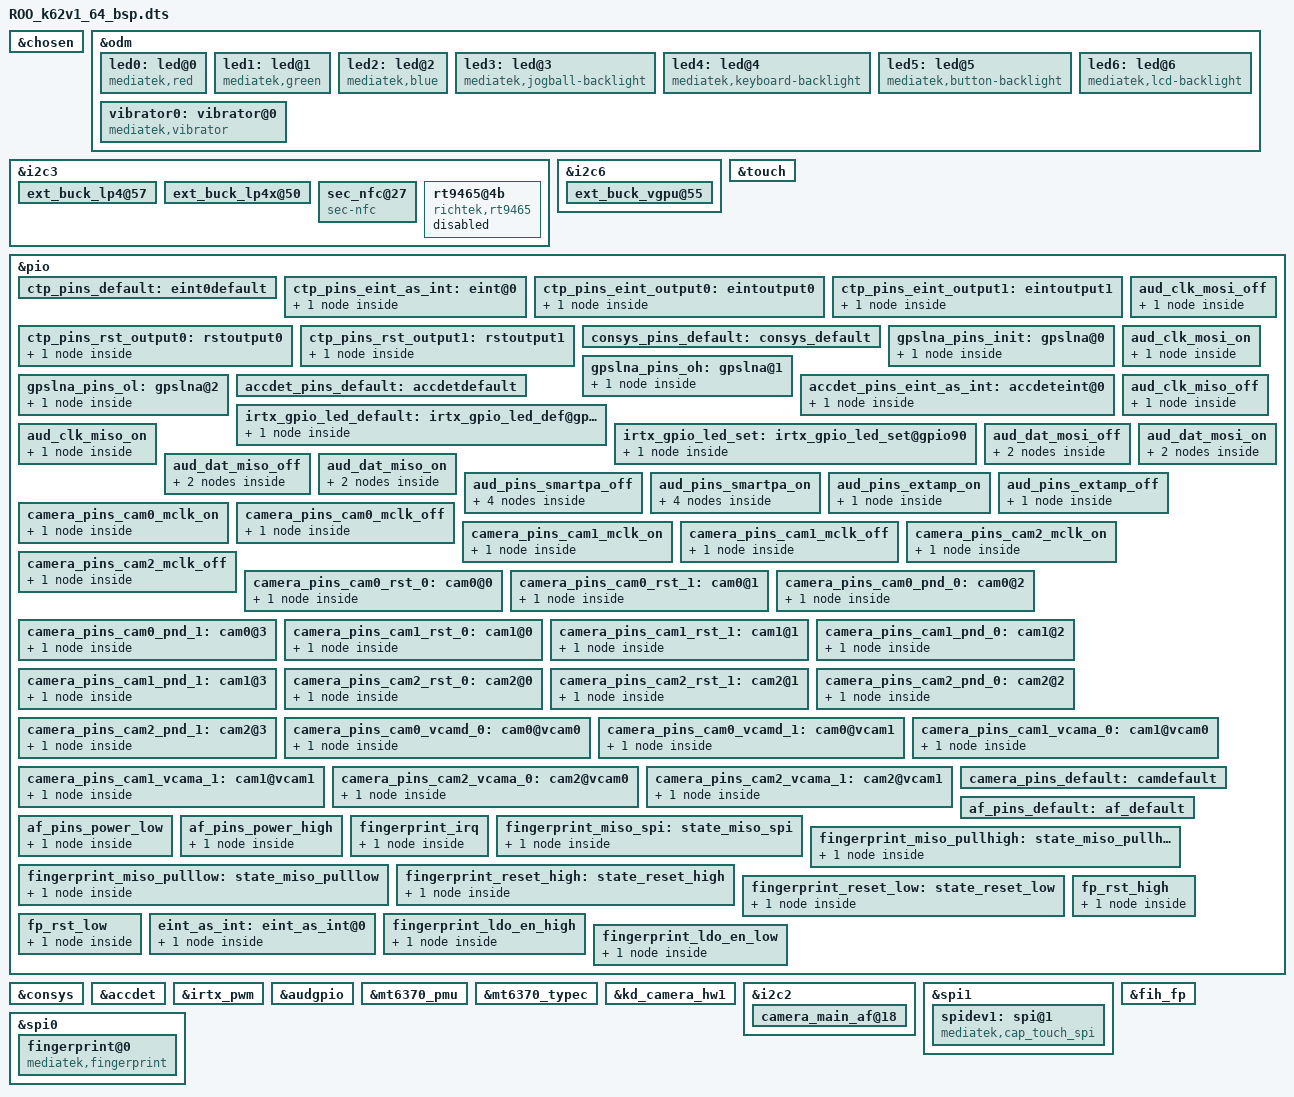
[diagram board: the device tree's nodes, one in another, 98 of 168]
#include <dt-bindings/interrupt-controller/arm-gic.h>
#include <dt-bindings/interrupt-controller/irq.h>
#include <dt-bindings/pinctrl/mt6765-pinfunc.h>
#include <dt-bindings/clock/mt6765-clk.h>

/dts-v1/;
/plugin/;

/* chosen */
&chosen {

	/* fpga may has no lk, we need to specify display info here */
	/* fb buffer is reserved using this dts by memory node above */
	atag,videolfb-fb_base_h = <0x0>;
	atag,videolfb-fb_base_l = <0x5e605000>;
	atag,videolfb-islcmfound = <1>;
	/* because no lk, so lcm is not inited */
	atag,videolfb-islcm_inited = <0>;
	atag,videolfb-fps= <6000>;
	atag,videolfb-vramSize= <0x017bb000>;
	atag,videolfb-lcmname= "ili9881h_hd720plus_dsi_vdo_dj";
};

&odm {
	led0:led@0 {
		compatible = "mediatek,red";
		led_mode = <0>;
		data = <1>;
		pwm_config = <0 0 0 0 0>;
	};
	led1:led@1 {
		compatible = "mediatek,green";
		led_mode = <0>;
		data = <1>;
		pwm_config = <0 0 0 0 0>;
	};
	led2:led@2 {
		compatible = "mediatek,blue";
		led_mode = <0>;
		data = <1>;
		pwm_config = <0 0 0 0 0>;
	};
	led3:led@3 {
		compatible = "mediatek,jogball-backlight";
		led_mode = <0>;
		data = <1>;
		pwm_config = <0 0 0 0 0>;
	};
	led4:led@4 {
		compatible = "mediatek,keyboard-backlight";
		led_mode = <0>;
		data = <1>;
		pwm_config = <0 0 0 0 0>;
	};
	led5:led@5 {
		compatible = "mediatek,button-backlight";
		led_mode = <0>;
		data = <1>;
		pwm_config = <0 0 0 0 0>;
	};
	led6:led@6 {
		compatible = "mediatek,lcd-backlight";
		led_mode = <5>;
		data = <1>;
		pwm_config = <0 3 0 0 0>;
	};
	vibrator0:vibrator@0 {
		compatible = "mediatek,vibrator";
		vib_timer = <50>;
		vib_limit = <0>;
		vib_vol= <9>;
	};
};

&i2c3 {
	ext_buck_lp4@57 {
		regulator-name ="ext_buck_vdd2";
		regulator-min-microvolt = <300000>;
		regulator-max-microvolt = <1300000>;
		vsel_pin = <0>;
	};

	ext_buck_lp4x@50 {
		regulator-name ="ext_buck_vddq";
		regulator-min-microvolt = <300000>;
		regulator-max-microvolt = <1300000>;
		vsel_pin = <1>;
	};
};

&i2c6 {
	ext_buck_vgpu@55 {
		regulator-name ="ext_buck_vgpu";
		regulator-min-microvolt = <300000>;
		regulator-max-microvolt = <1300000>;
		vsel_pin = <2>;
	};
};
/* TOUCH start */
&touch {
	tpd-resolution = <720 1440>;
	use-tpd-button = <0>;
	tpd-key-num = <3>;
	tpd-key-local= <139 172 158 0>;
	tpd-key-dim-local = <90 883 100 40 230 883 100 40 370 883 100 40 0 0 0 0>;
	tpd-max-touch-num = <5>;
	tpd-filter-enable = <1>;
	tpd-filter-pixel-density = <146>;
	tpd-filter-custom-prameters = <0 0 0 0 0 0 0 0 0 0 0 0>;
	tpd-filter-custom-speed = <0 0 0>;
	pinctrl-names = "default", "state_eint_as_int", "state_eint_output0", "state_eint_output1",
		"state_rst_output0", "state_rst_output1";
	pinctrl-0 = <&ctp_pins_default>;
	pinctrl-1 = <&ctp_pins_eint_as_int>;
	pinctrl-2 = <&ctp_pins_eint_output0>;
	pinctrl-3 = <&ctp_pins_eint_output1>;
	pinctrl-4 = <&ctp_pins_rst_output0>;
	pinctrl-5 = <&ctp_pins_rst_output1>;
	status = "okay";
};
&pio {
	ctp_pins_default: eint0default {
	};
	ctp_pins_eint_as_int: eint@0 {
		pins_cmd_dat {
			pinmux = <PINMUX_GPIO0__FUNC_GPIO0>;
			slew-rate = <0>;
			bias-disable;
		};
	};
	ctp_pins_eint_output0: eintoutput0 {
		pins_cmd_dat {
			pinmux = <PINMUX_GPIO0__FUNC_GPIO0>;
			slew-rate = <1>;
			output-low;
		};
	};
	ctp_pins_eint_output1: eintoutput1 {
		pins_cmd_dat {
			pinmux = <PINMUX_GPIO0__FUNC_GPIO0>;
			slew-rate = <1>;
			output-high;
		};
	};
	ctp_pins_rst_output0: rstoutput0 {
		pins_cmd_dat {
			pinmux = <PINMUX_GPIO174__FUNC_GPIO174>;
			slew-rate = <1>;
			output-low;
		};
	};
	ctp_pins_rst_output1: rstoutput1 {
		pins_cmd_dat {
			pinmux = <PINMUX_GPIO174__FUNC_GPIO174>;
			slew-rate = <1>;
			output-high;
		};
	};
};
/* TOUCH end */

/* CONSYS GPIO standardization */
&pio {
	consys_pins_default: consys_default {
	};
	gpslna_pins_init: gpslna@0 {
		pins_cmd_dat {
			pinmux = <PINMUX_GPIO91__FUNC_GPIO91>;
			slew-rate = <0>;
			bias-disable;
			output-low;
		};
	};
	gpslna_pins_oh: gpslna@1 {
		pins_cmd_dat {
			pinmux = <PINMUX_GPIO91__FUNC_GPIO91>;
			slew-rate = <1>;
			output-high;
		};
	};
	gpslna_pins_ol: gpslna@2 {
		pins_cmd_dat {
			pinmux = <PINMUX_GPIO91__FUNC_GPIO91>;
			slew-rate = <1>;
			output-low;
		};
	};
};
&consys {
	pinctrl-names = "default", "gps_lna_state_init",
		"gps_lna_state_oh", "gps_lna_state_ol";
	pinctrl-0 = <&consys_pins_default>;
	pinctrl-1 = <&gpslna_pins_init>;
	pinctrl-2 = <&gpslna_pins_oh>;
	pinctrl-3 = <&gpslna_pins_ol>;
	status = "okay";
};
/* CONSYS end */
/* J6000363 - edith.y.hu
   NFC I2C config @{ */
/* J6000504 - roy.zy.shang
   NFC I2C config @{ */
/* NFC start */
&i2c3 {
        sec_nfc@27 {
        compatible = "sec-nfc";
        reg = <0x27>;
        pvdd-gpio = <&pio 178 0x0>;
        ven-gpio = <&pio 173 0x0>;
        irq-gpio = <&pio 10 0x0>;
        firm-gpio = <&pio 172 0x0>;
        clk_req-gpio = <&pio 89 0x0>;
    };
};

/* NFC end */
/* NFC I2C config @} */

/* accdet start */
&accdet {
	accdet-mic-vol = <6>;
	headset-mode-setting = <0x500 0x500 1 0x1f0 0x800 0x800 0x20 0x44>;
	accdet-plugout-debounce = <1>;
	accdet-mic-mode = <1>;
	headset-eint-level-pol = <8>;
	headset-three-key-threshold = <0 80 220 400>;
	headset-three-key-threshold-CDD = <0 121 192 600>;
	headset-four-key-threshold = <0 58 121 192 400>;
	pinctrl-names = "default", "state_eint_as_int";
	pinctrl-0 = <&accdet_pins_default>;
	pinctrl-1 = <&accdet_pins_eint_as_int>;
	status = "okay";
};
&pio {
	accdet_pins_default: accdetdefault {
	};
	accdet_pins_eint_as_int: accdeteint@0 {
		pins_cmd_dat {
			pinmux = <PINMUX_GPIO9__FUNC_GPIO9>;
			slew-rate = <0>;
			bias-disable;
		};
	};
};
/* accdet end */

/* battery end */
/*&bat_gm30 {
	EMBEDDED_SEL = <(0)>;
};*/
/* battery end */

/* IRTX GPIO end */
&irtx_pwm {
	pinctrl-names = "irtx_gpio_led_default", "irtx_gpio_led_set";
	pinctrl-0 = <&irtx_gpio_led_default>;
	pinctrl-1 = <&irtx_gpio_led_set>;
	status = "okay";
};
&pio {
	irtx_gpio_led_default:irtx_gpio_led_def@gpio90 {
		pins_cmd_dat {
			pinmux = <PINMUX_GPIO90__FUNC_GPIO90>;
			slew-rate = <1>;
			bias-disable;
			output-low;
			input-schmitt-enable = <0>;
		};
	};

	irtx_gpio_led_set:irtx_gpio_led_set@gpio90 {
		pins_cmd_dat {
			pinmux = <PINMUX_GPIO90__FUNC_PWM0>;
			slew-rate = <1>;
			output-high;
		};
	};
};
/* IRTX GPIO Settings -End */

/* AUDIO GPIO standardization */
&audgpio {
	pinctrl-names = "aud_clk_mosi_off",
			"aud_clk_mosi_on",
			"aud_clk_miso_off",
			"aud_clk_miso_on",
			"aud_dat_mosi_off",
			"aud_dat_mosi_on",
			"aud_dat_miso_off",
			"aud_dat_miso_on",
			"aud_smartpa_off",
			"aud_smartpa_on",
			"extamp-pullhigh",
			"extamp-pulllow";
	pinctrl-0 = <&aud_clk_mosi_off>;
	pinctrl-1 = <&aud_clk_mosi_on>;
	pinctrl-2 = <&aud_clk_miso_off>;
	pinctrl-3 = <&aud_clk_miso_on>;
	pinctrl-4 = <&aud_dat_mosi_off>;
	pinctrl-5 = <&aud_dat_mosi_on>;
	pinctrl-6 = <&aud_dat_miso_off>;
	pinctrl-7 = <&aud_dat_miso_on>;
	pinctrl-8 = <&aud_pins_smartpa_off>;
	pinctrl-9 = <&aud_pins_smartpa_on>;
	pinctrl-10 = <&aud_pins_extamp_on>;
	pinctrl-11 = <&aud_pins_extamp_off>;
	status = "okay";
};

&pio {
	aud_clk_mosi_off: aud_clk_mosi_off {
		pins_cmd0_dat {
			pinmux = <PINMUX_GPIO136__FUNC_GPIO136>;
		};
	};

	aud_clk_mosi_on: aud_clk_mosi_on {
		pins_cmd0_dat {
			pinmux = <PINMUX_GPIO136__FUNC_AUD_CLK_MOSI>;
		};
	};

	aud_clk_miso_off: aud_clk_miso_off {
		pins_cmd0_dat {
			pinmux = <PINMUX_GPIO140__FUNC_GPIO140>;
		};
	};

	aud_clk_miso_on: aud_clk_miso_on {
		pins_cmd0_dat {
			pinmux = <PINMUX_GPIO140__FUNC_AUD_CLK_MISO>;
		};
	};

	aud_dat_mosi_off: aud_dat_mosi_off {
		pins_cmd1_dat {
			pinmux = <PINMUX_GPIO138__FUNC_GPIO138>;
			input-enable;
			slew-rate = <0>;
			bias-disable;
		};
		pins_cmd2_dat {
			pinmux = <PINMUX_GPIO139__FUNC_GPIO139>;
			input-enable;
			slew-rate = <0>;
			bias-disable;
		};
	};

	aud_dat_mosi_on: aud_dat_mosi_on {
		pins_cmd1_dat {
			pinmux = <PINMUX_GPIO138__FUNC_AUD_DAT_MOSI0>;
		};
		pins_cmd2_dat {
			pinmux = <PINMUX_GPIO139__FUNC_AUD_DAT_MOSI1>;
		};
	};

	aud_dat_miso_off: aud_dat_miso_off {
		pins_cmd1_dat {
			pinmux = <PINMUX_GPIO142__FUNC_GPIO142>;
			input-enable;
			slew-rate = <0>;
			bias-disable;
		};
		pins_cmd2_dat {
			pinmux = <PINMUX_GPIO143__FUNC_GPIO143>;
			input-enable;
			slew-rate = <0>;
			bias-disable;
		};
	};

	aud_dat_miso_on: aud_dat_miso_on {
		pins_cmd1_dat {
			pinmux = <PINMUX_GPIO142__FUNC_AUD_DAT_MISO0>;
		};
		pins_cmd2_dat {
			pinmux = <PINMUX_GPIO143__FUNC_AUD_DAT_MISO1>;
		};
	};

	aud_pins_smartpa_off: aud_pins_smartpa_off {
		pins_cmd0_dat {
			pinmux = <PINMUX_GPIO17__FUNC_GPIO17>;
		};
		pins_cmd1_dat {
			pinmux = <PINMUX_GPIO18__FUNC_GPIO18>;
		};
		pins_cmd2_dat {
			pinmux = <PINMUX_GPIO19__FUNC_GPIO19>;
		};
		pins_cmd3_dat {
			pinmux = <PINMUX_GPIO20__FUNC_GPIO20>;
		};
	};

	aud_pins_smartpa_on: aud_pins_smartpa_on {
		pins_cmd0_dat {
			pinmux = <PINMUX_GPIO17__FUNC_I2S0_DI>;
		};
		pins_cmd1_dat {
			pinmux = <PINMUX_GPIO18__FUNC_I2S3_BCK>;
		};
		pins_cmd2_dat {
			pinmux = <PINMUX_GPIO19__FUNC_I2S3_LRCK>;
		};
		pins_cmd3_dat {
			pinmux = <PINMUX_GPIO20__FUNC_I2S3_DO>;
		};
	};
    aud_pins_extamp_on:aud_pins_extamp_on{
        pins_cmd0_dat{
			pinmux = <PINMUX_GPIO159__FUNC_GPIO159>;
			slew-rate = <1>;
			output-high;
        };
    };
    aud_pins_extamp_off:aud_pins_extamp_off{
        pins_cmd0_dat{
			pinmux = <PINMUX_GPIO159__FUNC_GPIO159>;
			slew-rate = <1>;
			output-low;
		};
	};
};
/* AUDIO end */

&mt6370_pmu {
	mt6370,intr_gpio_num = <11>; /* direct defined GPIO num */
	mt6370,intr_gpio = <&pio 11 0x0>;
};

&mt6370_typec {
	mt6370pd,intr_gpio_num = <41>; /* direct defined GPIO num */
	mt6370pd,intr_gpio = <&pio 41 0x0>;
};

/*
&charger {
	algorithm_name = "DualSwitchCharging";
	chg1_ta_ac_charger_current = <2000000>;
	chg2_ta_ac_charger_current = <2000000>;
};
*/

&i2c3 {
	rt9465@4b {
		compatible = "richtek,rt9465";
		reg = <0x4b>;
		status = "disabled";
		rt,en_gpio_num = <176>;
		rt,en_gpio = <&pio 176 0x0>;
		rt,intr_gpio_num = <23>; /* direct defined GPIO num */
		rt,intr_gpio = <&pio 23 0x0>;
		interrupt-names = "wdtmri";
		charger_name = "secondary_chg";
		ichg = <1500000>; /* uA */
		mivr = <4500000>; /* uV */
		cv = <4550000>; /* uV */
		ieoc = <700000>; /* uA */
		safety_timer = <12>; /* hour */
		en_st; /* safety timer */
		/* en_te; */
		en_wdt;
	};
};

/* CAMERA GPIO standardization */
&pio {
	camera_pins_cam0_mclk_on: camera_pins_cam0_mclk_on {
		pins_cmd_dat {
			pinmux = <PINMUX_GPIO99__FUNC_CMMCLK0>;
		};
	};
	camera_pins_cam0_mclk_off: camera_pins_cam0_mclk_off {
		pins_cmd_dat {
			pinmux = <PINMUX_GPIO99__FUNC_GPIO99>;
		};
	};
	camera_pins_cam1_mclk_on: camera_pins_cam1_mclk_on {
		pins_cmd_dat {
			pinmux = <PINMUX_GPIO100__FUNC_CMMCLK1>;
		};
	};
	camera_pins_cam1_mclk_off: camera_pins_cam1_mclk_off {
		pins_cmd_dat {
			pinmux = <PINMUX_GPIO100__FUNC_GPIO100>;
		};
	};
	camera_pins_cam2_mclk_on: camera_pins_cam2_mclk_on {
		pins_cmd_dat {
			pinmux = <PINMUX_GPIO108__FUNC_CMMCLK2>;
		};
	};
	camera_pins_cam2_mclk_off: camera_pins_cam2_mclk_off {
		pins_cmd_dat {
			pinmux = <PINMUX_GPIO108__FUNC_GPIO108>;
		};
	};
	camera_pins_cam0_rst_0: cam0@0 {
		pins_cmd_dat {
			pinmux = <PINMUX_GPIO101__FUNC_GPIO101>;
			slew-rate = <1>; /*direction 0:in, 1:out*/
			output-low;/*direction out used only. output_low or high*/
		};
	};
	camera_pins_cam0_rst_1: cam0@1 {
		pins_cmd_dat {
			pinmux = <PINMUX_GPIO101__FUNC_GPIO101>;
			slew-rate = <1>;
			output-high;
		};
	};
	camera_pins_cam0_pnd_0: cam0@2 {
		pins_cmd_dat {
			pinmux = <PINMUX_GPIO150__FUNC_GPIO150>; /* main avdd */
			slew-rate = <1>;
			output-low;
		};
	};
	camera_pins_cam0_pnd_1: cam0@3 {
		pins_cmd_dat {
			pinmux = <PINMUX_GPIO150__FUNC_GPIO150>;
			slew-rate = <1>;
			output-high;
		};
	};
	camera_pins_cam1_rst_0: cam1@0 {
		pins_cmd_dat {
			pinmux = <PINMUX_GPIO102__FUNC_GPIO102>;
			slew-rate = <1>; /*direction 0:in, 1:out*/
			output-low;/*direction out used only. output_low or high*/
		};
	};
	camera_pins_cam1_rst_1: cam1@1 {
		pins_cmd_dat {
			pinmux = <PINMUX_GPIO102__FUNC_GPIO102>;
			slew-rate = <1>;
			output-high;
		};
	};
	camera_pins_cam1_pnd_0: cam1@2 {
		pins_cmd_dat {
			pinmux = <PINMUX_GPIO94__FUNC_GPIO94>;  /*FCAM1_DVDD_1P2_EN*/
			slew-rate = <1>;
			output-low;
		};
	};
	camera_pins_cam1_pnd_1: cam1@3 {
		pins_cmd_dat {
			pinmux = <PINMUX_GPIO94__FUNC_GPIO94>;/*FCAM1_DVDD_1P2_EN*/
			slew-rate = <1>;
			output-high;
		};
	};
	camera_pins_cam2_rst_0: cam2@0 {
		pins_cmd_dat {
			pinmux = <PINMUX_GPIO109__FUNC_GPIO109>;
			slew-rate = <1>;
			output-low;
		};
	};
	camera_pins_cam2_rst_1: cam2@1 {
		pins_cmd_dat {
			pinmux = <PINMUX_GPIO109__FUNC_GPIO109>;
			slew-rate = <1>;
			output-high;
		};
	};
	camera_pins_cam2_pnd_0: cam2@2 {
		pins_cmd_dat {
			pinmux = <PINMUX_GPIO151__FUNC_GPIO151>; /* main2 dvdd */
			slew-rate = <1>;
			output-low;
		};
	};
	camera_pins_cam2_pnd_1: cam2@3 {
		pins_cmd_dat {
			pinmux = <PINMUX_GPIO151__FUNC_GPIO151>;
			slew-rate = <1>;
			output-high;
		};
	};
	camera_pins_cam0_vcamd_0: cam0@vcam0 {
		pins_cmd_dat {
			pinmux = <PINMUX_GPIO152__FUNC_GPIO152>;
			slew-rate = <1>;
			output-low;
		};
	};
	camera_pins_cam0_vcamd_1: cam0@vcam1 {
		pins_cmd_dat {
			pinmux = <PINMUX_GPIO152__FUNC_GPIO152>;
			slew-rate = <1>;
			output-high;
		};
	};
/*Front Camera Start*/
	camera_pins_cam1_vcama_0: cam1@vcam0 {
		pins_cmd_dat {
			pinmux = <PINMUX_GPIO151__FUNC_GPIO151>; /* FCAM1_AVDD_2P8_EN */
			slew-rate = <1>;
			output-low;
		};
	};
	camera_pins_cam1_vcama_1: cam1@vcam1 {
		pins_cmd_dat {
			pinmux = <PINMUX_GPIO151__FUNC_GPIO151>; /* FCAM1_AVDD_2P8_EN */
			slew-rate = <1>;
			output-high;
		};
	};
/*Front Camera End*/
	camera_pins_cam2_vcama_0: cam2@vcam0 {
		pins_cmd_dat {
			pinmux = <PINMUX_GPIO176__FUNC_GPIO176>;
			slew-rate = <1>;
			output-low;
		};
	};
	camera_pins_cam2_vcama_1: cam2@vcam1 {
		pins_cmd_dat {
			pinmux = <PINMUX_GPIO176__FUNC_GPIO176>;
			slew-rate = <1>;
			output-high;
		};
	};

	camera_pins_default: camdefault {
	};
};
&kd_camera_hw1 {
	pinctrl-names = "default",
			"cam0_rst0", "cam0_rst1",
			"cam0_pnd0", "cam0_pnd1",
			"cam1_rst0", "cam1_rst1",
			"cam1_pnd0", "cam1_pnd1",
			"cam2_rst0", "cam2_rst1",
			"cam2_pnd0", "cam2_pnd1",
			"cam_ldo_vcamd_0", "cam_ldo_vcamd_1",
			"cam_ldo_sub_vcama_0", "cam_ldo_sub_vcama_1",
			"cam_ldo_main2_vcama_0", "cam_ldo_main2_vcama_1",
			"cam0_mclk_off", "cam0_mclk_on",
			"cam1_mclk_off", "cam1_mclk_on",
			"cam2_mclk_off", "cam2_mclk_on";
	pinctrl-0 = <&camera_pins_default>;
	pinctrl-1 = <&camera_pins_cam0_rst_0>;
	pinctrl-2 = <&camera_pins_cam0_rst_1>;
	pinctrl-3 = <&camera_pins_cam0_pnd_0>;
	pinctrl-4 = <&camera_pins_cam0_pnd_1>;
	pinctrl-5 = <&camera_pins_cam1_rst_0>;
	pinctrl-6 = <&camera_pins_cam1_rst_1>;
	pinctrl-7 = <&camera_pins_cam1_pnd_0>;
	pinctrl-8 = <&camera_pins_cam1_pnd_1>;
	pinctrl-9 = <&camera_pins_cam2_rst_0>;
	pinctrl-10 = <&camera_pins_cam2_rst_1>;
	pinctrl-11 = <&camera_pins_cam2_pnd_0>;
	pinctrl-12 = <&camera_pins_cam2_pnd_1>;
	pinctrl-13 = <&camera_pins_cam0_vcamd_0>;
	pinctrl-14 = <&camera_pins_cam0_vcamd_1>;
	pinctrl-15 = <&camera_pins_cam1_vcama_0>; /*Front Camera Start*/
	pinctrl-16 = <&camera_pins_cam1_vcama_1>; /*Front Camera End*/
	pinctrl-17 = <&camera_pins_cam2_vcama_0>;
	pinctrl-18 = <&camera_pins_cam2_vcama_1>;
	pinctrl-19 = <&camera_pins_cam0_mclk_off>;
	pinctrl-20 = <&camera_pins_cam0_mclk_on>;
	pinctrl-21 = <&camera_pins_cam1_mclk_off>;
	pinctrl-22 = <&camera_pins_cam1_mclk_on>;
	pinctrl-23 = <&camera_pins_cam2_mclk_off>;
	pinctrl-24 = <&camera_pins_cam2_mclk_on>;

	cam0_vcamio-supply = <&mt_pmic_vcamio_ldo_reg>;
	cam0_vldo28-supply = <&mt_pmic_vldo28_ldo_reg>;
	cam0_vcamaf-supply = <&mt_pmic_vldo28_ldo_reg>;
	cam1_vcamio-supply = <&mt_pmic_vcamio_ldo_reg>;
	cam1_vcamd-supply = <&mt_pmic_vcamd_ldo_reg>;	
	cam2_vcamio-supply = <&mt_pmic_vcamio_ldo_reg>;
	cam2_vcama-supply = <&mt_pmic_vcama_ldo_reg>;
	cam2_vcamd-supply = <&mt_pmic_vcamd_ldo_reg>;
	status = "okay";
};

&pio {
	af_pins_default: af_default {
	};
	af_pins_power_low: af_pins_power_low {
		pins_cmd_dat {
			pinmux = <PINMUX_GPIO176__FUNC_GPIO176>;
			slew-rate = <0>;
			bias-disable;
			output-low;
		};
	};
	af_pins_power_high: af_pins_power_high {
		pins_cmd_dat {
			pinmux = <PINMUX_GPIO176__FUNC_GPIO176>;
			slew-rate = <1>;
			output-high;
		};
	};
};
/*AF VCM gpio */

&i2c2 {
	camera_main_af@18 {
	afvdd-gpio = <&pio 176 0x00>;
	pinctrl-names = "default", "af_high", "af_low";
	pinctrl-0 = <&af_pins_default>;
	pinctrl-1 = <&af_pins_power_high>;
	pinctrl-2 = <&af_pins_power_low>;
	status = "okay";
	};
};

/*tp zero flash spi test*/
&spi1{ 


     status ="okay";



     #address-cells = <1>;



     #size-cells = <0>;



    spidev1:spi@1{



     //compatible ="mediatek,spi-mt65xx-test";
      compatible = "mediatek,cap_touch_spi";



     reg =<0>;



     spi-max-frequency= <8000000>; 


  };
};
/*end of tp zero flash spi test*/

/* FINGERPRINT start */
&spi0 {
	#address-cells = <1>;
        #size-cells = <0>;
	
	fingerprint@0{
	// goodix_fp@0{
		compatible = "mediatek,fingerprint";
		//compatible = "mediatek,goodix-fp";
		reg = <0>;
		spi-max-frequency = <8000000>;
		netlink-event = <30>; //26
		status = "okay";
	};
};

 &fih_fp {
	pinctrl-names = "fingerprint_irq", "miso_spi", "miso_pullhigh", "miso_pulllow", "reset_high", "reset_low", "fp_rst_high", "fp_rst_low", "eint_as_int","fingerprint_ldo_en_high","fingerprint_ldo_en_low";
	pinctrl-0 = <&fingerprint_irq>;
	pinctrl-1 = <&fingerprint_miso_spi>;
	pinctrl-2 = <&fingerprint_miso_pullhigh>;
	pinctrl-3 = <&fingerprint_miso_pulllow>;
	pinctrl-4 = <&fingerprint_reset_high>;
	pinctrl-5 = <&fingerprint_reset_low>;
	pinctrl-6 = <&fp_rst_high>;
	pinctrl-7 = <&fp_rst_low>;
	pinctrl-8 = <&eint_as_int>;
        pinctrl-9 = <&fingerprint_ldo_en_high>;
	pinctrl-10 = <&fingerprint_ldo_en_low>;
	status = "okay";
	
};



&pio {
	fingerprint_irq: fingerprint_irq {
		pins_cmd_dat {
			pinmux = <PINMUX_GPIO3__FUNC_GPIO3>;
			slew-rate = <0>;
			bias-disable;
		};
	};

	fingerprint_miso_spi: state_miso_spi {
		pins_cmd_dat {
			pinmux = <PINMUX_GPIO155__FUNC_SPI0_MI>;
		};
	};

	fingerprint_miso_pullhigh: state_miso_pullhigh {
		pins_cmd_dat {
			pinmux = <PINMUX_GPIO155__FUNC_GPIO155>;
			slew-rate = <1>;
			output-high;
		};
	};

	fingerprint_miso_pulllow: state_miso_pulllow {
		pins_cmd_dat {
			pinmux = <PINMUX_GPIO155__FUNC_GPIO155>;
			slew-rate = <1>;
			output-low;
		};
	};

	fingerprint_reset_high: state_reset_high {
		pins_cmd_dat {
			pinmux = <PINMUX_GPIO175__FUNC_GPIO175>;
			slew-rate = <1>;
			output-high;
		};
	};

	fingerprint_reset_low: state_reset_low {
		pins_cmd_dat {
			pinmux = <PINMUX_GPIO175__FUNC_GPIO175>;
			slew-rate = <1>;
			output-low;
		};
	};

	fp_rst_high: fp_rst_high {
		pins_cmd_dat {
			pinmux = <PINMUX_GPIO175__FUNC_GPIO175>;
			slew-rate = <1>;
			output-high;
		};
	};

	fp_rst_low: fp_rst_low {
		pins_cmd_dat {
			pinmux = <PINMUX_GPIO175__FUNC_GPIO175>;
			slew-rate = <1>;
			output-low;
		};
	};

	eint_as_int: eint_as_int@0 {
		pins_cmd_dat {
			pinmux = <PINMUX_GPIO3__FUNC_GPIO3>;
			slew-rate = <0>;
			bias-pull-down = <00>;
		};
	};

	
        fingerprint_ldo_en_high: fingerprint_ldo_en_high {
                pins_cmd_dat {
                        pinmux = <PINMUX_GPIO153__FUNC_GPIO153>;
                        slew-rate = <1>;
                	output-high;
		};
        };

	fingerprint_ldo_en_low: fingerprint_ldo_en_low {
                pins_cmd_dat {
                        pinmux = <PINMUX_GPIO153__FUNC_GPIO153>;
                        slew-rate = <1>;
                	output-low;
		};
        };
 	
	
};
&fih_fp {
			interrupt-parent = <&pio>;
			interrupts = <3 IRQ_TYPE_EDGE_RISING 3 0>;
			status = "okay";
	};


/*FINGERPRINT GPIO standardization  add by microarray */
/*
&mas_finger{
	pinctrl-names = "default", "finger_power_en0","finger_power_en1","finger_reset_en0","finger_reset_en1","finger_spi0_mi_as_spi0_mi","finger_spi0_mi_as_gpio",
                          "finger_spi0_mo_as_spi0_mo","finger_spi0_mo_as_gpio","finger_spi0_clk_as_spi0_clk","finger_spi0_clk_as_gpio","finger_spi0_cs_as_spi0_cs",
                          "finger_spi0_cs_as_gpio","finger_int_as_int";
	pinctrl-0 = <&finger_pins_default>;
	pinctrl-1 = <&finger_power_en0>;
	pinctrl-2 = <&finger_power_en1>;
	pinctrl-3 = <&finger_reset_en0>;
	pinctrl-4 = <&finger_reset_en1>;
	pinctrl-5 = <&finger_spi0_mi_as_spi0_mi>;
	pinctrl-6 = <&finger_spi0_mi_as_gpio>;
	pinctrl-7 = <&finger_spi0_mo_as_spi0_mo>;
	pinctrl-8 = <&finger_spi0_mo_as_gpio>;
	pinctrl-9 = <&finger_spi0_clk_as_spi0_clk>;
	pinctrl-10= <&finger_spi0_clk_as_gpio>;
	pinctrl-11= <&finger_spi0_cs_as_spi0_cs>;
	pinctrl-12= <&finger_spi0_cs_as_gpio>;
	pinctrl-13= <&finger_int_as_int>;
};
&mas_finger {

interrupt-parent = <&pio>;
interrupts = <3 IRQ_TYPE_EDGE_RISING 3 0>;
status = "okay";
};


&pio {
	finger_pins_default:finger_pins_default{
	};
	finger_power_en0:finger_power_en@0{
		    pins_cmd_dat {
					
			pins = <PINMUX_GPIO153__FUNC_GPIO153>;
			slew-rate = <1>;
			output-low;
		};
	};
	finger_power_en1:finger_power_en@1{
		    pins_cmd_dat {
			pins = <PINMUX_GPIO153__FUNC_GPIO153>;
			slew-rate = <1>;
			output-high;
		};
	};
	finger_reset_en0:finger_reset_en@0{
		    pins_cmd_dat {
			pins = <PINMUX_GPIO175__FUNC_GPIO175>;
			slew-rate = <1>;
			output-low;
		};
	};
	finger_reset_en1:finger_reset_en@1{
		    pins_cmd_dat {
			pins = <PINMUX_GPIO175__FUNC_GPIO175>;
			slew-rate = <1>;
			output-high;
		};
	};
	finger_spi0_mi_as_spi0_mi:finger_spi0_mi_as_spi0_mi@0{
		    pins_cmd_dat {
			pins = <PINMUX_GPIO155__FUNC_SPI0_MI>;
			slew-rate = <0>;
			bias-disable;
			output-low;
			input-schmitt-enable = <0>;
		};
	};
	finger_spi0_mi_as_gpio:finger_spi0_mi_as_gpio@0{
		    pins_cmd_dat {
			pins = <PINMUX_GPIO155__FUNC_GPIO155>;
			slew-rate = <0>;
			output-low;
			input-schmitt-enable = <0>;
		};
	};
	finger_spi0_mo_as_spi0_mo:finger_spi0_mo_as_spi0_mo@0{
		    pins_cmd_dat {
					
			pins = <PINMUX_GPIO157__FUNC_SPI0_MO>;
			slew-rate = <1>;
			bias-disable;
			output-low;
			input-schmitt-enable = <0>;
		};
	};
	finger_spi0_mo_as_gpio:finger_spi0_mo_as_gpio@0{
		    pins_cmd_dat {
			pins = <PINMUX_GPIO157__FUNC_GPIO157>;
			slew-rate = <1>;
			output-low;
			input-schmitt-enable = <0>;
		};
	};
	finger_spi0_clk_as_spi0_clk:finger_spi0_clk_as_spi0_clk@0{
		    pins_cmd_dat {
			pins = <PINMUX_GPIO158__FUNC_SPI0_CLK>;
			slew-rate = <1>;
			bias-disable;
			output-low;
			input-schmitt-enable = <0>;
		};
	};
	finger_spi0_clk_as_gpio:finger_spi0_clk_as_gpio@0{
		    pins_cmd_dat {
			pins = <PINMUX_GPIO158__FUNC_GPIO158>;
			slew-rate = <1>;
			output-low;
			input-schmitt-enable = <0>;
		};
	};
	finger_spi0_cs_as_spi0_cs:finger_spi0_cs_as_spi0_cs@0{
		    pins_cmd_dat {
			pins = <PINMUX_GPIO156__FUNC_SPI0_CSB>;
			slew-rate = <1>;
			bias-disable;
			output-low;
			input-schmitt-enable = <0>;
		};
	};
	finger_spi0_cs_as_gpio:finger_spi0_cs_as_gpio@0{
		    pins_cmd_dat {
			pins = <PINMUX_GPIO156__FUNC_GPIO156>;
			slew-rate = <1>;
			output-low;
			input-schmitt-enable = <0>;
		};
	};
	finger_int_as_int: finger_int_as_int@0{
			pins_cmd_dat {
				pins = <PINMUX_GPIO3__FUNC_GPIO3>;
				slew-rate = <0>;
				bias-pull-up = <00>;
			};
	};
};

*/
/*FINGERPRINT GPIO end*/



/* FINGERPRINT end */
#include <k62v1_64_bsp/cust.dtsi>
/*End of this file, DO NOT ADD ANYTHING HERE*/
